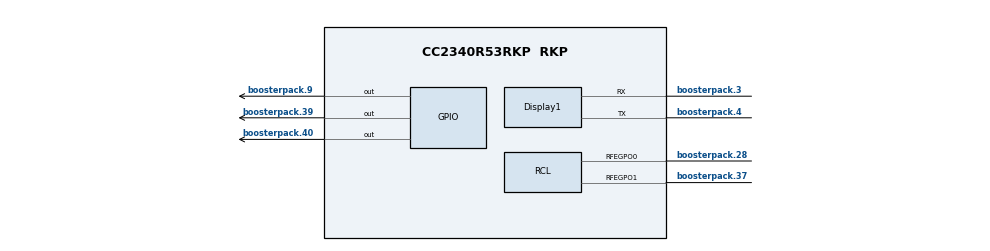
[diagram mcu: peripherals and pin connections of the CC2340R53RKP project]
/**
 * @cliArgs --board "/ti/boards/LP_EM_CC2340R53" --device "CC2340R53RKP" --part "Default" --package "RKP" --rtos "freertos" --product "simplelink_lowpower_f3_sdk@9.11.00.18"
 * @versions {"tool":"1.23.2+4156"}
 */

/**
 * Import the modules used in this configuration.
 */
const FreeRTOS    = scripting.addModule("/freertos/FreeRTOS");
const ble         = scripting.addModule("/ti/ble/ble");
const CCFG        = scripting.addModule("/ti/devices/CCFG");
const rfdesign    = scripting.addModule("/ti/devices/radioconfig/rfdesign");
const Display     = scripting.addModule("/ti/display/Display");
const Display1    = Display.addInstance();
const AESCCM      = scripting.addModule("/ti/drivers/AESCCM");
const AESCCM1     = AESCCM.addInstance();
const AESCTRDRBG  = scripting.addModule("/ti/drivers/AESCTRDRBG");
const AESCTRDRBG1 = AESCTRDRBG.addInstance();
const AESECB      = scripting.addModule("/ti/drivers/AESECB");
const AESECB1     = AESECB.addInstance();
const ECDH        = scripting.addModule("/ti/drivers/ECDH");
const ECDH1       = ECDH.addInstance();
const GPIO        = scripting.addModule("/ti/drivers/GPIO");
const GPIO1       = GPIO.addInstance();
const GPIO2       = GPIO.addInstance();
const GPIO3       = GPIO.addInstance();
const NVS         = scripting.addModule("/ti/drivers/NVS");
const NVS1        = NVS.addInstance();
const Power       = scripting.addModule("/ti/drivers/Power");
const RCL         = scripting.addModule("/ti/drivers/RCL");
const RNG         = scripting.addModule("/ti/drivers/RNG");
const RNG1        = RNG.addInstance();
const Button      = scripting.addModule("/ti/drivers/apps/Button", {}, false);
const Button1     = Button.addInstance();
const Button2     = Button.addInstance();
const Settings    = scripting.addModule("/ti/posix/freertos/Settings");

/**
 * Write custom configuration values to the imported modules.
 */
FreeRTOS.timerStackSize = 0x00000190;
FreeRTOS.idleStackSize  = 0x00000130;
FreeRTOS.heapSize       = 0x0000B400;

ble.basicBLE                                                   = true;
ble.disDevBySerUuid                                            = true;
ble.deviceName                                                 = "Basic BLE project";
ble.numOfAdvSets                                               = 1;
ble.numOfDefAdvSets                                            = 1;
ble.maxPDUSize                                                 = 255;
ble.deviceRole                                                 = "PERIPHERAL_CFG+CENTRAL_CFG";
ble.maxPDUNum                                                  = 255;
ble.bondIOCaps                                                 = "GAPBOND_IO_CAP_NO_INPUT_NO_OUTPUT";
ble.defaultTxPowerValue                                        = "8";
ble.addressMode                                                = "ADDRMODE_PUBLIC";
ble.maxConnNum                                                 = 2;
ble.eccDebugKeys                                               = true;
ble.radioConfig.codeExportConfig.$name                         = "ti_devices_radioconfig_code_export_param0";
ble.adcNoiseConfig.codeExportConfig.$name                      = "ti_devices_radioconfig_code_export_param1";
ble.bleCsConfig.codeExportConfig.$name                         = "ti_devices_radioconfig_code_export_param2";
ble.connUpdateParamsPeripheral.$name                           = "ti_ble_general_ble_conn_update_params0";
ble.advSet1.$name                                              = "ti_ble_broadcaster_advertisement_set0";
ble.advSet1.advParam1.$name                                    = "ti_ble_broadcaster_advertisement_params0";
ble.advSet1.advParam1.primIntMin                               = 30;
ble.advSet1.advParam1.primIntMax                               = 30;
ble.advSet1.advData1.$name                                     = "ti_ble_broadcaster_advertisement_data0";
ble.advSet1.advData1.GAP_ADTYPE_16BIT_MORE                     = true;
ble.advSet1.advData1.numOfUUIDs16More                          = 1;
ble.advSet1.advData1.UUID016More                               = 0xFFF0;
ble.advSet1.scanRes1.$name                                     = "ti_ble_broadcaster_advertisement_data1";
ble.advSet1.scanRes1.GAP_ADTYPE_PERIPHERAL_CONN_INTERVAL_RANGE = true;
ble.connUpdateParamsCentral.$name                              = "ti_ble_general_ble_conn_update_params1";

CCFG.ccfgTemplate.$name = "ti_devices_CCFG_CCFGCC23X0Template0";

Display1.$name                          = "CONFIG_Display_0";
Display1.$hardware                      = system.deviceData.board.components.XDS110UART;
Display1.uartBufferSize                 = 128;
Display1.uart.$name                     = "CONFIG_DISPLAY_UART";
Display1.uart.txPinInstance.$name       = "CONFIG_PIN_UART_TX";
Display1.uart.rxPinInstance.$name       = "CONFIG_PIN_UART_RX";
Display1.uart.uart.$assign              = "UART0";
Display1.uart.uart.dmaTxChannel.$assign = "DMA_CH1";
Display1.uart.uart.dmaRxChannel.$assign = "DMA_CH0";
Display1.uart.uart.txPin.$assign        = "boosterpack.4";
Display1.uart.uart.rxPin.$assign        = "boosterpack.3";

AESCCM1.$name = "CONFIG_AESCCM0";

AESCTRDRBG1.$name = "CONFIG_AESCTRDRBG_0";

AESECB1.$name = "CONFIG_AESECB0";

ECDH1.$name = "CONFIG_ECDH0";

GPIO1.$hardware       = system.deviceData.board.components.LED_GREEN;
GPIO1.$name           = "CONFIG_GPIO_LED_GREEN";
GPIO1.gpioPin.$assign = "boosterpack.40";

GPIO2.$hardware       = system.deviceData.board.components.LED_RED;
GPIO2.$name           = "CONFIG_GPIO_LED_RED";
GPIO2.gpioPin.$assign = "boosterpack.39";

GPIO3.$name           = "CONFIG_GPIO_0";
GPIO3.mode            = "Output";
GPIO3.gpioPin.$assign = "boosterpack.9";

NVS1.$name                    = "CONFIG_NVSINTERNAL";
NVS1.internalFlash.$name      = "ti_drivers_nvs_NVSLPF30";
NVS1.internalFlash.regionBase = 0x7D000;
NVS1.internalFlash.regionSize = 0x3000;

RCL.useCase                    = ["rfDebugSignals"];
RCL.lrfGpio.$assign            = "LRF";
RCL.lrfGpio.rfegpo0Pin.$assign = "boosterpack.28";
RCL.lrfGpio.rfegpo1Pin.$assign = "boosterpack.37";

RNG.rngReturnBehavior = "RNG_RETURN_BEHAVIOR_BLOCKING";

RNG1.$name = "CONFIG_RNG_0";

Button1.$name          = "CONFIG_BUTTON_0";
Button1.$hardware      = system.deviceData.board.components["BTN-1"];
Button1.button.$assign = "boosterpack.13";

Button2.$name          = "CONFIG_BUTTON_1";
Button2.$hardware      = system.deviceData.board.components["BTN-2"];
Button2.button.$assign = "boosterpack.12";
